# AT90CAN128 register map
Vendor: Atmel; File version: 1.0
CPU: other r0p0, little endian, no MPU, no FPU, 4 interrupt priority bits
Registers are 8-bit, read-write, reset 0x0 unless marked. A register's access mark holds for its fields unless they carry their own. Offsets are from the block's base; [hi:lo] are bit positions; {n}, {i} and the like mark numbered series.

## JTAG — JTAG Interface
Base 0x00800051
0x00 OCDR — On-Chip Debug Related Register in I/O Memory (write-only for debugger)
0x03 MCUSR — MCU Status Register (read-only for debugger)
  [4] JTRF — JTAG Reset Flag
0x04 MCUCR — MCU Control Register
  [7] JTD — JTAG Interface Disable

## PORTA — I/O Port
Base 0x00800020
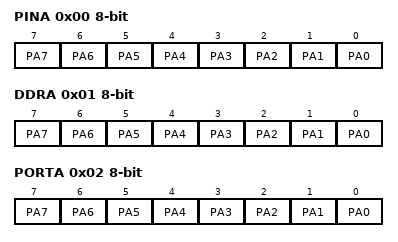
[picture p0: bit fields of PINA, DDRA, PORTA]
0x00 PINA — Port A Input Pins (read-only for debugger)
  [n] PA{n} (n=0..7) — Pin A{n}
0x01 DDRA — Port A Data Direction Register
  [n] PA{n} (n=0..7) — Pin A{n}
0x02 PORTA — Port A Data Register
  [n] PA{n} (n=0..7) — Pin A{n}

## PORTB — I/O Port
Base 0x00800023
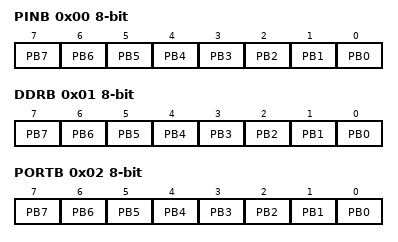
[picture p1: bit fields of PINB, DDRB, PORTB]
0x00 PINB — Port B Input Pins (read-only for debugger)
  [n] PB{n} (n=0..7) — Pin B{n}
0x01 DDRB — Port B Data Direction Register
  [n] PB{n} (n=0..7) — Pin B{n}
0x02 PORTB — Port B Data Register
  [n] PB{n} (n=0..7) — Pin B{n}

## PORTC — I/O Port
Base 0x00800026
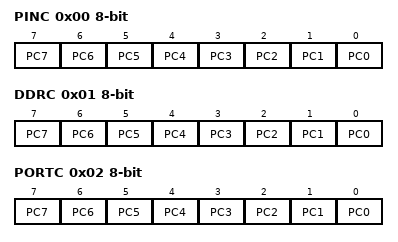
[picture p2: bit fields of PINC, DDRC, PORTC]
0x00 PINC — Port C Input Pins (read-only for debugger)
  [n] PC{n} (n=0..7) — Pin C{n}
0x01 DDRC — Port C Data Direction Register
  [n] PC{n} (n=0..7) — Pin C{n}
0x02 PORTC — Port C Data Register
  [n] PC{n} (n=0..7) — Pin C{n}

## PORTD — I/O Port
Base 0x00800029
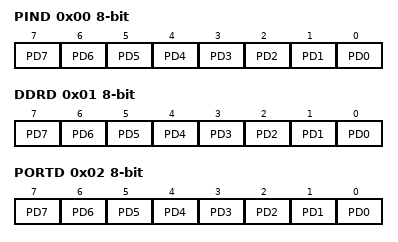
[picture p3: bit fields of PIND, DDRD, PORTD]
0x00 PIND — Port D Input Pins (read-only for debugger)
  [n] PD{n} (n=0..7) — Pin D{n}
0x01 DDRD — Port D Data Direction Register
  [n] PD{n} (n=0..7) — Pin D{n}
0x02 PORTD — Port D Data Register
  [n] PD{n} (n=0..7) — Pin D{n}

## PORTE — I/O Port
Base 0x0080002C
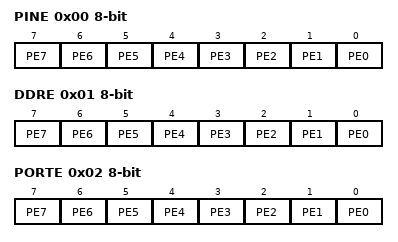
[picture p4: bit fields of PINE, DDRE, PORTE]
0x00 PINE — Input Pins, Port E (read-only for debugger)
  [n] PE{n} (n=0..7) — Pin E{n}
0x01 DDRE — Data Direction Register, Port E
  [n] PE{n} (n=0..7) — Pin E{n}
0x02 PORTE — Data Register, Port E
  [n] PE{n} (n=0..7) — Pin E{n}

## PORTF — I/O Port
Base 0x0080002F
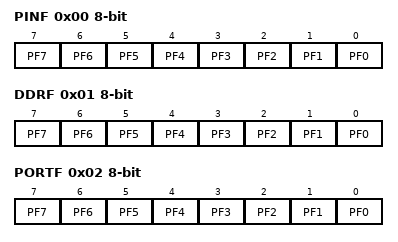
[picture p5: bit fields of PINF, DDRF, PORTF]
0x00 PINF — Input Pins, Port F (read-only for debugger)
  [n] PF{n} (n=0..7) — Pin F{n}
0x01 DDRF — Data Direction Register, Port F
  [n] PF{n} (n=0..7) — Pin F{n}
0x02 PORTF — Data Register, Port F
  [n] PF{n} (n=0..7) — Pin F{n}

## PORTG — I/O Port
Base 0x00800032
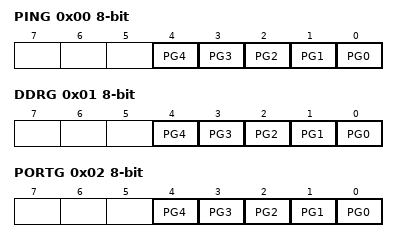
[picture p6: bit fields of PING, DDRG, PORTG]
0x00 PING — Input Pins, Port G (read-only for debugger)
  [n] PG{n} (n=0..4) — Pin G{n}
0x01 DDRG — Data Direction Register, Port G
  [n] PG{n} (n=0..4) — Pin G{n}
0x02 PORTG — Data Register, Port G
  [n] PG{n} (n=0..4) — Pin G{n}

## SPI — Serial Peripheral Interface
Base 0x0080004C
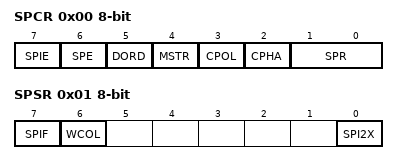
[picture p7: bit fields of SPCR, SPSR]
0x00 SPCR — SPI Control Register
  [7] SPIE — SPI Interrupt Enable
  [6] SPE — SPI Enable
  [5] DORD — Data Order
  [4] MSTR — Master/Slave Select
  [3] CPOL — Clock polarity
  [2] CPHA — Clock Phase
  [1:0] SPR — SPI Clock Rate Selects
    0=FOSC_4; 1=FOSC_16; 3=FOSC_128
0x01 SPSR — SPI Status Register (read-only for debugger)
  [7] SPIF — SPI Interrupt Flag
  [6] WCOL — Write Collision Flag
  [0] SPI2X — Double SPI Speed Bit
0x02 SPDR — SPI Data Register (write-only for debugger)
  [7:0] SPD — SPI Data Register

## TC0 — Timer/Counter, 8-bit
Base 0x00800035
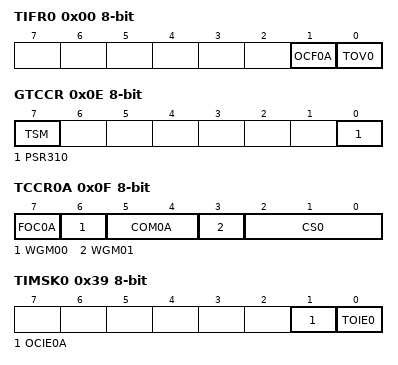
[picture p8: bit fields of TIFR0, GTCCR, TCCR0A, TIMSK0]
0x00 TIFR0 — Timer/Counter0 Interrupt Flag register (read-only for debugger)
  [1] OCF0A — Timer/Counter0 Output Compare Flag 0
  [0] TOV0 — Timer/Counter0 Overflow Flag
0x0E GTCCR — General Timer/Control Register
  [7] TSM — Timer/Counter Synchronization Mode
  [0] PSR310 — Prescaler Reset Timer/Counter1 and Timer/Counter0
0x0F TCCR0A — Timer/Counter0 Control Register
  [7] FOC0A — Force Output Compare
  [6] WGM00 — Waveform Generation Mode 0
    0=NORMAL; 1=CTC
  [5:4] COM0A — Compare Match Output Modes
  [3] WGM01 — Waveform Generation Mode 1
  [2:0] CS0 — Clock Selects
    0=NO_CLOCK_SOURCE_STOPPED; 1=RUNNING_NO_PRESCALING; 2=RUNNING_CLK_8; 3=RUNNING_CLK_64; 4=RUNNING_CLK_256; 5=RUNNING_CLK_1024; 6=RUNNING_EXTCLK_TN_FALLING_EDGE; 7=RUNNING_EXTCLK_TN_RISING_EDGE
0x11 TCNT0 — Timer/Counter0
0x12 OCR0A — Timer/Counter0 Output Compare Register
  [7:0] OCR0A — Output Compare A bits
0x39 TIMSK0 — Timer/Counter0 Interrupt Mask Register
  [1] OCIE0A — Timer/Counter0 Output Compare Match Interrupt Enable
  [0] TOIE0 — Timer/Counter0 Overflow Interrupt Enable
